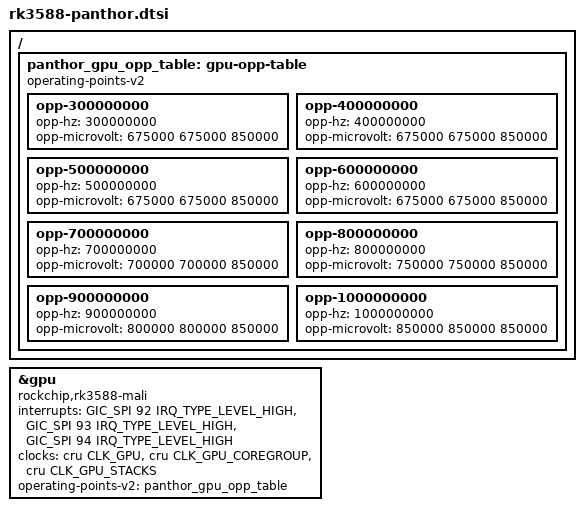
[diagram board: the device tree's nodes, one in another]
// SPDX-License-Identifier: (GPL-2.0+ OR MIT)
/* GPU OPPs: Linux v6.12 rk3588-opp.dtsi, Rockchip Electronics.
 * No SLPad-specific voltage, frequency or silicon-bin tuning.
 * Vendor PVTM/bin selection is not implemented by Panthor.
 */

/delete-node/ &gpu_opp_table;

&gpu {
 compatible = "rockchip,rk3588-mali", "arm,mali-valhall-csf";
 interrupts = <GIC_SPI 92 IRQ_TYPE_LEVEL_HIGH>, <GIC_SPI 93 IRQ_TYPE_LEVEL_HIGH>, <GIC_SPI 94 IRQ_TYPE_LEVEL_HIGH>;
 interrupt-names = "job", "mmu", "gpu";
 clocks = <&cru CLK_GPU>, <&cru CLK_GPU_COREGROUP>, <&cru CLK_GPU_STACKS>;
 clock-names = "core", "coregroup", "stacks";
 /delete-property/ assigned-clocks;
 /delete-property/ assigned-clock-rates;
 /delete-property/ upthreshold;
 /delete-property/ downdifferential;
};


/ {
	panthor_gpu_opp_table: gpu-opp-table {
		compatible = "operating-points-v2";
		opp-300000000 {
			opp-hz = /bits/ 64 <300000000>;
			opp-microvolt = <675000 675000 850000>;
		};
		opp-400000000 {
			opp-hz = /bits/ 64 <400000000>;
			opp-microvolt = <675000 675000 850000>;
		};
		opp-500000000 {
			opp-hz = /bits/ 64 <500000000>;
			opp-microvolt = <675000 675000 850000>;
		};
		opp-600000000 {
			opp-hz = /bits/ 64 <600000000>;
			opp-microvolt = <675000 675000 850000>;
		};
		opp-700000000 {
			opp-hz = /bits/ 64 <700000000>;
			opp-microvolt = <700000 700000 850000>;
		};
		opp-800000000 {
			opp-hz = /bits/ 64 <800000000>;
			opp-microvolt = <750000 750000 850000>;
		};
		opp-900000000 {
			opp-hz = /bits/ 64 <900000000>;
			opp-microvolt = <800000 800000 850000>;
		};
		opp-1000000000 {
			opp-hz = /bits/ 64 <1000000000>;
			opp-microvolt = <850000 850000 850000>;
		};
	};
};

&gpu {
	operating-points-v2 = <&panthor_gpu_opp_table>;
};
